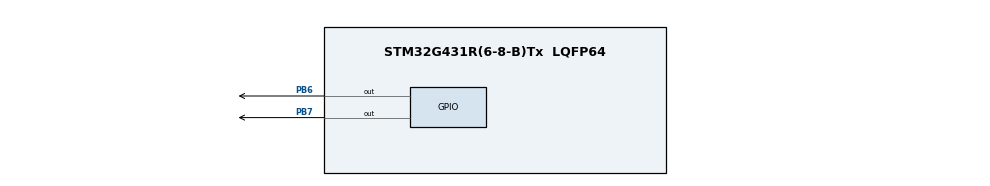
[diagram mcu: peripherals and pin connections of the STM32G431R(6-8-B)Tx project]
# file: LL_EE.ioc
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Mcu.Family=STM32G4
Mcu.Name=STM32G431R(6-8-B)Tx
Mcu.Package=LQFP64
NVIC.PriorityGroup=NVIC_PRIORITYGROUP_4
PB6.Signal=GPIO_Output
PB7.Signal=GPIO_Output
PF0-OSC_IN.Mode=HSE-External-Oscillator
PF0-OSC_IN.Signal=RCC_OSC_IN
PF1-OSC_OUT.Mode=HSE-External-Oscillator
PF1-OSC_OUT.Signal=RCC_OSC_OUT
ProjectManager.HeapSize=0x200
ProjectManager.StackSize=0x400
ProjectManager.TargetToolchain=MDK-ARM V5.27
RCC.ADC12Freq_Value=80000000
RCC.AHBFreq_Value=80000000
RCC.APB1Freq_Value=80000000
RCC.APB1TimFreq_Value=80000000
RCC.APB2Freq_Value=80000000
RCC.APB2TimFreq_Value=80000000
RCC.CortexFreq_Value=80000000
RCC.EXTERNAL_CLOCK_VALUE=12288000
RCC.HCLKFreq_Value=80000000
RCC.HSE_VALUE=24000000
RCC.HSI48_VALUE=48000000
RCC.HSI_VALUE=16000000
RCC.LSE_VALUE=32768
RCC.PLLM=RCC_PLLM_DIV2
RCC.PLLN=20
RCC.SYSCLKFreq_VALUE=80000000
RCC.SYSCLKSource=RCC_SYSCLKSOURCE_PLLCLK
RCC.USBFreq_Value=80000000
RCC.VCOOutputFreq_Value=160000000
VP_SYS_VS_DBSignals.Mode=DisableDeadBatterySignals
board=custom

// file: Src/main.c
/* USER CODE BEGIN Header */
/**
  ******************************************************************************
  * @file           : main.c
  * @brief          : Main program body
  ******************************************************************************
  * @attention
  *
  * <h2><center>&copy; Copyright (c) 2021 STMicroelectronics.
  * All rights reserved.</center></h2>
  *
  * This software component is licensed by ST under BSD 3-Clause license,
  * the "License"; You may not use this file except in compliance with the
  * License. You may obtain a copy of the License at:
  *                        opensource.org/licenses/BSD-3-Clause
  *
  ******************************************************************************
  */
/* USER CODE END Header */

#include "main.h"

void SystemClock_Config(void);
static void MX_GPIO_Init(void);

/* USER CODE BEGIN 0 */
//
uint8_t x24c02_read(uint8_t address)
{
	unsigned char val;

	I2CStart();
	I2CSendByte(0xa0);
	I2CWaitAck();

	I2CSendByte(address);
	I2CWaitAck();

	I2CStart();
	I2CSendByte(0xa1);
	I2CWaitAck();
	val = I2CReceiveByte();
	I2CWaitAck();
	I2CStop();

	return(val);
}

//
void x24c02_write(unsigned char address,unsigned char info)
{
	I2CStart();
	I2CSendByte(0xa0);
	I2CWaitAck();

	I2CSendByte(address);
	I2CWaitAck();
	I2CSendByte(info);
	I2CWaitAck();
	I2CStop();
}
/* USER CODE END 0 */

int main(void)
{
  /* USER CODE BEGIN 1 */
	uint8_t val = 0;
	char buf[20];
  /* USER CODE END 1 */

  /* MCU Configuration--------------------------------------------------------*/

  /* Reset of all peripherals, Initializes the Flash interface and the Systick. */

  LL_APB2_GRP1_EnableClock(LL_APB2_GRP1_PERIPH_SYSCFG);
  LL_APB1_GRP1_EnableClock(LL_APB1_GRP1_PERIPH_PWR);

  NVIC_SetPriorityGrouping(NVIC_PRIORITYGROUP_4);

  /* System interrupt init*/

  /** Disable the internal Pull-Up in Dead Battery pins of UCPD peripheral
  */
  LL_PWR_DisableDeadBatteryPD();

  /* Configure the system clock */
  SystemClock_Config();

  /* Initialize all configured peripherals */
  MX_GPIO_Init();
  /* USER CODE BEGIN 2 */
	I2CInit();
	LCD_Init();

	LCD_Clear(Blue);
	LCD_SetBackColor(Blue);
	LCD_SetTextColor(White);

	LCD_DisplayStringLine(Line0, (uint8_t *)"                    ");
	LCD_DisplayStringLine(Line1, (uint8_t *)"                    ");
	LCD_DisplayStringLine(Line2, (uint8_t *)"       EE Test      ");
	LCD_DisplayStringLine(Line3, (uint8_t *)"                    ");
	LCD_DisplayStringLine(Line4, (uint8_t *)"                    ");

	LCD_SetBackColor(White);
	LCD_SetTextColor(Blue);

	LCD_DisplayStringLine(Line5, (uint8_t *)"                    ");
	LCD_DisplayStringLine(Line6, (uint8_t *)"       ADDR:0       ");
	LCD_DisplayStringLine(Line7, (uint8_t *)"                    ");
	LCD_DisplayStringLine(Line8, (uint8_t *)"                    ");
	LCD_DisplayStringLine(Line9, (uint8_t *)"                    ");
  /* USER CODE END 2 */

	val = x24c02_read(0);
	x24c02_write(0, ++val);

  /* Infinite loop */
  while (1)
  {
		LCD_SetTextColor(Red);
		sprintf(buf, "      PWR CNTR:%d    ", val);
		LCD_DisplayStringLine(Line8, (uint8_t *)(buf));
  }
}

void SystemClock_Config(void)
{
  LL_FLASH_SetLatency(LL_FLASH_LATENCY_3);

   if(LL_FLASH_GetLatency() != LL_FLASH_LATENCY_3)
  {
    Error_Handler();
  }
  LL_PWR_SetRegulVoltageScaling(LL_PWR_REGU_VOLTAGE_SCALE1);
  LL_RCC_HSI_Enable();

   /* Wait till HSI is ready */
  while(LL_RCC_HSI_IsReady() != 1)
  {

  }
  LL_RCC_HSI_SetCalibTrimming(64);
  LL_RCC_PLL_ConfigDomain_SYS(LL_RCC_PLLSOURCE_HSI, LL_RCC_PLLM_DIV_2, 20, LL_RCC_PLLR_DIV_2);
  LL_RCC_PLL_EnableDomain_SYS();
  LL_RCC_PLL_Enable();

   /* Wait till PLL is ready */
  while(LL_RCC_PLL_IsReady() != 1)
  {

  }
  LL_RCC_SetSysClkSource(LL_RCC_SYS_CLKSOURCE_PLL);

   /* Wait till System clock is ready */
  while(LL_RCC_GetSysClkSource() != LL_RCC_SYS_CLKSOURCE_STATUS_PLL)
  {

  }
  /* Set AHB prescaler*/
  LL_RCC_SetAHBPrescaler(LL_RCC_SYSCLK_DIV_1);
  LL_RCC_SetAPB1Prescaler(LL_RCC_APB1_DIV_1);
  LL_RCC_SetAPB2Prescaler(LL_RCC_APB1_DIV_1);

  LL_Init1msTick(80000000);

  LL_SetSystemCoreClock(80000000);
}

static void MX_GPIO_Init(void)
{
  LL_GPIO_InitTypeDef GPIO_InitStruct = {0};

  /* GPIO Ports Clock Enable */
  LL_AHB2_GRP1_EnableClock(LL_AHB2_GRP1_PERIPH_GPIOF);
  LL_AHB2_GRP1_EnableClock(LL_AHB2_GRP1_PERIPH_GPIOB);

  /**/
  LL_GPIO_ResetOutputPin(GPIOB, LL_GPIO_PIN_6);

  /**/
  LL_GPIO_ResetOutputPin(GPIOB, LL_GPIO_PIN_7);

  /**/
  GPIO_InitStruct.Pin = LL_GPIO_PIN_6;
  GPIO_InitStruct.Mode = LL_GPIO_MODE_OUTPUT;
  GPIO_InitStruct.Speed = LL_GPIO_SPEED_FREQ_LOW;
  GPIO_InitStruct.OutputType = LL_GPIO_OUTPUT_PUSHPULL;
  GPIO_InitStruct.Pull = LL_GPIO_PULL_NO;
  LL_GPIO_Init(GPIOB, &GPIO_InitStruct);

  /**/
  GPIO_InitStruct.Pin = LL_GPIO_PIN_7;
  GPIO_InitStruct.Mode = LL_GPIO_MODE_OUTPUT;
  GPIO_InitStruct.Speed = LL_GPIO_SPEED_FREQ_LOW;
  GPIO_InitStruct.OutputType = LL_GPIO_OUTPUT_PUSHPULL;
  GPIO_InitStruct.Pull = LL_GPIO_PULL_NO;
  LL_GPIO_Init(GPIOB, &GPIO_InitStruct);

}

void Error_Handler(void)
{
}

/************************ (C) COPYRIGHT STMicroelectronics *****END OF FILE****/
